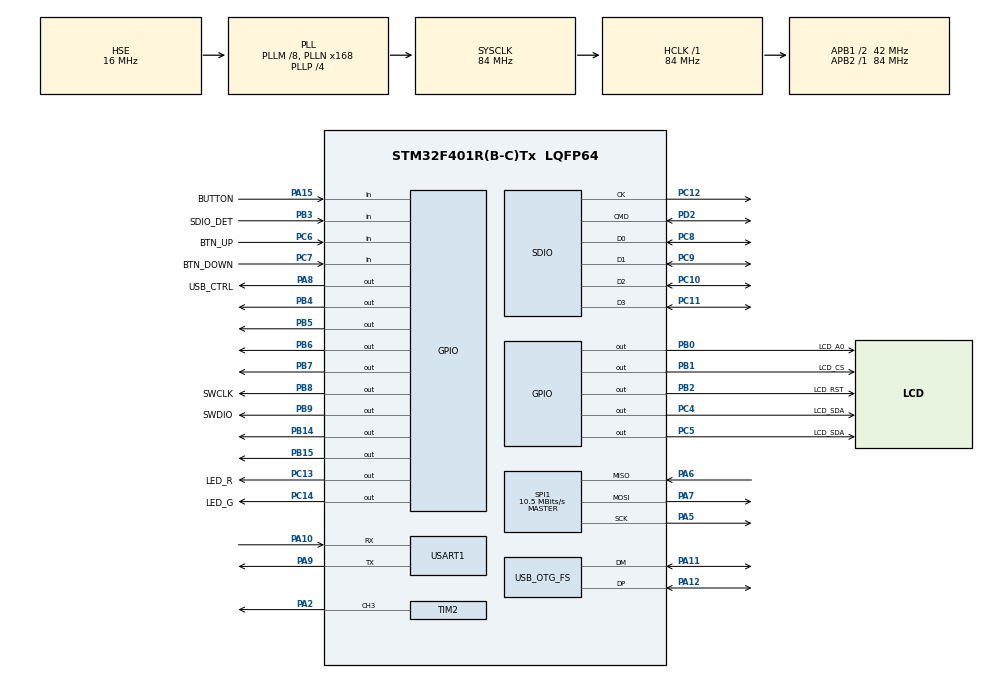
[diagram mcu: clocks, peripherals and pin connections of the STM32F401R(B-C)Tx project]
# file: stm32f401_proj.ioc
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FATFS.BSP.number=1
FATFS._USE_LFN=2
FATFS0.BSP.STBoard=false
FATFS0.BSP.api=Unknown
FATFS0.BSP.instance=PB3
FATFS0.BSP.ip=GPIO
FATFS0.BSP.mode=Input
FATFS0.BSP.name=Detect_SDIO
FATFS0.BSP.solution=PB3
Mcu.Family=STM32F4
Mcu.Name=STM32F401R(B-C)Tx
Mcu.Package=LQFP64
NVIC.OTG_FS_IRQn=true\:0\:0\:false\:false\:true\:false\:true\:true
NVIC.PriorityGroup=NVIC_PRIORITYGROUP_4
PA10.Mode=Asynchronous
PA10.Signal=USART1_RX
PA11.Mode=Device_Only
PA11.Signal=USB_OTG_FS_DM
PA12.Mode=Device_Only
PA12.Signal=USB_OTG_FS_DP
PA13.Mode=Serial_Wire
PA13.Signal=SYS_JTMS-SWDIO
PA14.Mode=Serial_Wire
PA14.Signal=SYS_JTCK-SWCLK
PA15.GPIO_Label=BUTTON
PA15.Signal=GPIO_Input
PA2.Signal=S_TIM2_CH3
PA5.Mode=Full_Duplex_Master
PA5.Signal=SPI1_SCK
PA6.Mode=Full_Duplex_Master
PA6.Signal=SPI1_MISO
PA7.Mode=Full_Duplex_Master
PA7.Signal=SPI1_MOSI
PA8.GPIO_Label=USB_CTRL
PA8.Signal=GPIO_Output
PA9.Mode=Asynchronous
PA9.Signal=USART1_TX
PB0.GPIO_Label=LCD_A0
PB0.Signal=GPIO_Output
PB1.GPIO_Label=LCD_CS
PB1.Signal=GPIO_Output
PB14.Signal=GPIO_Output
PB15.Signal=GPIO_Output
PB2.GPIO_Label=LCD_RST
PB2.Signal=GPIO_Output
PB3.GPIO_Label=SDIO_DET
PB3.Signal=GPIO_Input
PB4.Signal=GPIO_Output
PB5.Signal=GPIO_Output
PB6.Signal=GPIO_Output
PB7.Signal=GPIO_Output
PB8.GPIO_Label=SWCLK
PB8.Signal=GPIO_Output
PB9.GPIO_Label=SWDIO
PB9.Signal=GPIO_Output
PC10.Mode=SD_4_bits_Wide_bus
PC10.Signal=SDIO_D2
PC11.Mode=SD_4_bits_Wide_bus
PC11.Signal=SDIO_D3
PC12.Mode=SD_4_bits_Wide_bus
PC12.Signal=SDIO_CK
PC13-ANTI_TAMP.GPIO_Label=LED_R
PC13-ANTI_TAMP.Signal=GPIO_Output
PC14-OSC32_IN.GPIO_Label=LED_G
PC14-OSC32_IN.Signal=GPIO_Output
PC4.GPIO_Label=LCD_SDA
PC4.Signal=GPIO_Output
PC5.GPIO_Label=LCD_SDA
PC5.Signal=GPIO_Output
PC6.GPIO_Label=BTN_UP
PC6.GPIO_PuPd=GPIO_PULLUP
PC6.Signal=GPIO_Input
PC7.GPIO_Label=BTN_DOWN
PC7.GPIO_PuPd=GPIO_PULLUP
PC7.Signal=GPIO_Input
PC8.Mode=SD_4_bits_Wide_bus
PC8.Signal=SDIO_D0
PC9.Mode=SD_4_bits_Wide_bus
PC9.Signal=SDIO_D1
PD2.Mode=SD_4_bits_Wide_bus
PD2.Signal=SDIO_CMD
PH0\ -\ OSC_IN.Mode=HSE-External-Oscillator
PH0\ -\ OSC_IN.Signal=RCC_OSC_IN
PH1\ -\ OSC_OUT.Mode=HSE-External-Oscillator
PH1\ -\ OSC_OUT.Signal=RCC_OSC_OUT
ProjectManager.HeapSize=0x200
ProjectManager.StackSize=0x1000
ProjectManager.TargetToolchain=MDK-ARM V5.32
RCC.48MHZClocksFreq_Value=48000000
RCC.AHBFreq_Value=84000000
RCC.APB1CLKDivider=RCC_HCLK_DIV2
RCC.APB1Freq_Value=42000000
RCC.APB1TimFreq_Value=84000000
RCC.APB2Freq_Value=84000000
RCC.APB2TimFreq_Value=84000000
RCC.CortexFreq_Value=84000000
RCC.HCLKFreq_Value=84000000
RCC.HSE_VALUE=16000000
RCC.HSI_VALUE=16000000
RCC.LSE_VALUE=32768
RCC.PLLM=8
RCC.PLLN=168
RCC.PLLP=RCC_PLLP_DIV4
RCC.PLLQ=7
RCC.SYSCLKFreq_VALUE=84000000
RCC.SYSCLKSource=RCC_SYSCLKSOURCE_PLLCLK
RCC.VCOOutputFreq_Value=336000000
SDIO.ClockDiv=5
SH.S_TIM2_CH3.0=TIM2_CH3,PWM Generation3 CH3
SPI1.CalculateBaudRate=10.5 MBits/s
SPI1.Direction=SPI_DIRECTION_2LINES
SPI1.Mode=SPI_MODE_MASTER
SPI1.VirtualType=VM_MASTER
TIM2.AutoReloadPreload=TIM_AUTORELOAD_PRELOAD_ENABLE
TIM2.Channel-PWM\ Generation3\ CH3=TIM_CHANNEL_3
TIM2.Period=369
TIM2.Prescaler=83
TIM2.Pulse-PWM\ Generation3\ CH3=185
USART1.VirtualMode=VM_ASYNC
USB_DEVICE.CLASS_NAME_FS=CDC
USB_DEVICE.VirtualMode=Cdc
USB_DEVICE.VirtualModeFS=Cdc_FS
USB_OTG_FS.VirtualMode=Device_Only
VP_FATFS_VS_SDIO.Mode=SDIO
VP_USB_DEVICE_VS_USB_DEVICE_CDC_FS.Mode=CDC_FS
board=custom

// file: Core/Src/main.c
/* USER CODE BEGIN Header */
/**
  ******************************************************************************
  * @file           : main.c
  * @brief          : Main program body
  ******************************************************************************
  * @attention
  *
  * Copyright (c) 2026 STMicroelectronics.
  * All rights reserved.
  *
  * This software is licensed under terms that can be found in the LICENSE file
  * in the root directory of this software component.
  * If no LICENSE file comes with this software, it is provided AS-IS.
  *
  ******************************************************************************
  */
/* USER CODE END Header */
#include "main.h"
#include "fatfs.h"
#include "usb_device.h"

/* USER CODE BEGIN Includes */
#include "app_main.h"
/* USER CODE END Includes */

SD_HandleTypeDef hsd;

SPI_HandleTypeDef hspi1;

TIM_HandleTypeDef htim2;

UART_HandleTypeDef huart1;

void SystemClock_Config(void);
static void MX_GPIO_Init(void);
static void MX_SDIO_SD_Init(void);
static void MX_SPI1_Init(void);
static void MX_USART1_UART_Init(void);
static void MX_TIM2_Init(void);

int main(void)
{

  /* MCU Configuration--------------------------------------------------------*/

  /* Reset of all peripherals, Initializes the Flash interface and the Systick. */
  HAL_Init();

  /* Configure the system clock */
  SystemClock_Config();

  /* Initialize all configured peripherals */
  MX_GPIO_Init();
  MX_SDIO_SD_Init();
  MX_SPI1_Init();
  MX_USART1_UART_Init();
  MX_TIM2_Init();
  MX_FATFS_Init();
  MX_USB_DEVICE_Init();
  /* USER CODE BEGIN 2 */
	  HAL_GPIO_WritePin(USB_CTRL_GPIO_Port, USB_CTRL_Pin, GPIO_PIN_SET);

  /* 复位源打印（IWDG/欠压/软复位一眼分辨，产线诊断用）*/
  {
    uint32_t csr = RCC->CSR;
    const char *src = (csr & (1U << 24)) ? "IWDG" :
                      (csr & (1U << 19)) ? "WWDG" :
                      (csr & (1U << 26)) ? "SOFT" :
                      (csr & (1U << 28)) ? "POR" : "?";
    {   /* 必须 bsp_uart_log：裸 printf 无调试器时走半主机会挂死（实测教训）*/
        extern int bsp_uart_log(const char *fmt, ...);
        bsp_uart_log("[RST] src=%s csr=%08lX\n", src, (unsigned long)csr);
    }
  }
  app_main_init();   /* 应用层初始化：装配 LED 设备等 */
  /* USER CODE END 2 */

  /* Infinite loop */
  while (1)
  {

    /* USER CODE BEGIN 3 */
    app_main_loop();   /* 应用层主循环：LED 闪烁等 */
  }
  /* USER CODE END 3 */
}

void SystemClock_Config(void)
{
  RCC_OscInitTypeDef RCC_OscInitStruct = {0};
  RCC_ClkInitTypeDef RCC_ClkInitStruct = {0};

  /** Configure the main internal regulator output voltage
  */
  __HAL_RCC_PWR_CLK_ENABLE();
  __HAL_PWR_VOLTAGESCALING_CONFIG(PWR_REGULATOR_VOLTAGE_SCALE2);

  /** Initializes the RCC Oscillators according to the specified parameters
  * in the RCC_OscInitTypeDef structure.
  */
  RCC_OscInitStruct.OscillatorType = RCC_OSCILLATORTYPE_HSE;
  RCC_OscInitStruct.HSEState = RCC_HSE_ON;
  RCC_OscInitStruct.PLL.PLLState = RCC_PLL_ON;
  RCC_OscInitStruct.PLL.PLLSource = RCC_PLLSOURCE_HSE;
  RCC_OscInitStruct.PLL.PLLM = 8;
  RCC_OscInitStruct.PLL.PLLN = 168;
  RCC_OscInitStruct.PLL.PLLP = RCC_PLLP_DIV4;
  RCC_OscInitStruct.PLL.PLLQ = 7;
  if (HAL_RCC_OscConfig(&RCC_OscInitStruct) != HAL_OK)
  {
    Error_Handler();
  }

  /** Initializes the CPU, AHB and APB buses clocks
  */
  RCC_ClkInitStruct.ClockType = RCC_CLOCKTYPE_HCLK|RCC_CLOCKTYPE_SYSCLK
                              |RCC_CLOCKTYPE_PCLK1|RCC_CLOCKTYPE_PCLK2;
  RCC_ClkInitStruct.SYSCLKSource = RCC_SYSCLKSOURCE_PLLCLK;
  RCC_ClkInitStruct.AHBCLKDivider = RCC_SYSCLK_DIV1;
  RCC_ClkInitStruct.APB1CLKDivider = RCC_HCLK_DIV2;
  RCC_ClkInitStruct.APB2CLKDivider = RCC_HCLK_DIV1;

  if (HAL_RCC_ClockConfig(&RCC_ClkInitStruct, FLASH_LATENCY_2) != HAL_OK)
  {
    Error_Handler();
  }
}

static void MX_SDIO_SD_Init(void)
{

  hsd.Instance = SDIO;
  hsd.Init.ClockEdge = SDIO_CLOCK_EDGE_RISING;
  hsd.Init.ClockBypass = SDIO_CLOCK_BYPASS_DISABLE;
  hsd.Init.ClockPowerSave = SDIO_CLOCK_POWER_SAVE_DISABLE;
  hsd.Init.BusWide = SDIO_BUS_WIDE_1B;
  /* SDIO 写可靠性（实测 USB CDC + SD 写同跑时 f_write 间歇 FR_DISK_ERR）：
   *  - 硬件流控 ENABLE 实测反而让写立即失败（F401 SDIO 流控硅片 bug）→ 保持 DISABLED
   *  - 根因：轮询喂写 FIFO，USB 中断偶发抢 CPU → FIFO 欠载。降时钟给 CPU 充裕余量。
   *  → ClockDiv 5→30（SDIO_CK≈48/(30+2)=1.5MHz）。读随之变慢但稳定。
   *    后续若要提速，改 SDIO DMA（DMA 喂 FIFO 不抢 CPU）。*/
  hsd.Init.HardwareFlowControl = SDIO_HARDWARE_FLOW_CONTROL_DISABLE;
  hsd.Init.ClockDiv = 30;

}

static void MX_SPI1_Init(void)
{

  /* SPI1 parameter configuration*/
  hspi1.Instance = SPI1;
  hspi1.Init.Mode = SPI_MODE_MASTER;
  hspi1.Init.Direction = SPI_DIRECTION_2LINES;
  hspi1.Init.DataSize = SPI_DATASIZE_8BIT;
  hspi1.Init.CLKPolarity = SPI_POLARITY_LOW;
  hspi1.Init.CLKPhase = SPI_PHASE_1EDGE;
  hspi1.Init.NSS = SPI_NSS_SOFT;
  /* ST7789 SPI 写时序 max 16MHz。APB2=84MHz：/2=42MHz 严重超速 → 局部花屏
   * （实测：红色区花屏、白/绿/蓝正常 —— 0xF800 字节流直流分量最不平衡最易错）。
   * /8=10.5MHz，规格内留 35% 裕量；全屏刷 115KB ≈ 90ms。 */
  hspi1.Init.BaudRatePrescaler = SPI_BAUDRATEPRESCALER_8;
  hspi1.Init.FirstBit = SPI_FIRSTBIT_MSB;
  hspi1.Init.TIMode = SPI_TIMODE_DISABLE;
  hspi1.Init.CRCCalculation = SPI_CRCCALCULATION_DISABLE;
  hspi1.Init.CRCPolynomial = 10;
  if (HAL_SPI_Init(&hspi1) != HAL_OK)
  {
    Error_Handler();
  }

}

static void MX_TIM2_Init(void)
{

  TIM_MasterConfigTypeDef sMasterConfig = {0};
  TIM_OC_InitTypeDef sConfigOC = {0};

  htim2.Instance = TIM2;
  htim2.Init.Prescaler = 83;
  htim2.Init.CounterMode = TIM_COUNTERMODE_UP;
  htim2.Init.Period = 369;
  htim2.Init.ClockDivision = TIM_CLOCKDIVISION_DIV1;
  htim2.Init.AutoReloadPreload = TIM_AUTORELOAD_PRELOAD_ENABLE;
  if (HAL_TIM_PWM_Init(&htim2) != HAL_OK)
  {
    Error_Handler();
  }
  sMasterConfig.MasterOutputTrigger = TIM_TRGO_RESET;
  sMasterConfig.MasterSlaveMode = TIM_MASTERSLAVEMODE_DISABLE;
  if (HAL_TIMEx_MasterConfigSynchronization(&htim2, &sMasterConfig) != HAL_OK)
  {
    Error_Handler();
  }
  sConfigOC.OCMode = TIM_OCMODE_PWM1;
  sConfigOC.Pulse = 185;
  sConfigOC.OCPolarity = TIM_OCPOLARITY_HIGH;
  sConfigOC.OCFastMode = TIM_OCFAST_DISABLE;
  if (HAL_TIM_PWM_ConfigChannel(&htim2, &sConfigOC, TIM_CHANNEL_3) != HAL_OK)
  {
    Error_Handler();
  }
  HAL_TIM_MspPostInit(&htim2);

}

static void MX_USART1_UART_Init(void)
{

  huart1.Instance = USART1;
  huart1.Init.BaudRate = 115200;
  huart1.Init.WordLength = UART_WORDLENGTH_8B;
  huart1.Init.StopBits = UART_STOPBITS_1;
  huart1.Init.Parity = UART_PARITY_NONE;
  huart1.Init.Mode = UART_MODE_TX_RX;
  huart1.Init.HwFlowCtl = UART_HWCONTROL_NONE;
  huart1.Init.OverSampling = UART_OVERSAMPLING_16;
  if (HAL_UART_Init(&huart1) != HAL_OK)
  {
    Error_Handler();
  }

}

static void MX_GPIO_Init(void)
{
  GPIO_InitTypeDef GPIO_InitStruct = {0};

  /* GPIO Ports Clock Enable */
  __HAL_RCC_GPIOC_CLK_ENABLE();
  __HAL_RCC_GPIOH_CLK_ENABLE();
  __HAL_RCC_GPIOA_CLK_ENABLE();
  __HAL_RCC_GPIOB_CLK_ENABLE();
  __HAL_RCC_GPIOD_CLK_ENABLE();

  /*Configure GPIO pin Output Level */
  HAL_GPIO_WritePin(GPIOC, LED_R_Pin|LED_G_Pin|LCD_SDA_Pin|LCD_SDAC5_Pin
                          |GPIO_PIN_6|GPIO_PIN_7, GPIO_PIN_RESET);

  /*Configure GPIO pin Output Level */
  HAL_GPIO_WritePin(GPIOB, LCD_A0_Pin|LCD_CS_Pin|LCD_RST_Pin|GPIO_PIN_14
                          |GPIO_PIN_15|GPIO_PIN_4|GPIO_PIN_5|GPIO_PIN_6
                          |GPIO_PIN_7|SWCLK_Pin|SWDIO_Pin, GPIO_PIN_RESET);

  /*Configure GPIO pin Output Level */
  HAL_GPIO_WritePin(USB_CTRL_GPIO_Port, USB_CTRL_Pin, GPIO_PIN_RESET);

  /*Configure GPIO pins : LED_R_Pin LED_G_Pin LCD_SDA_Pin LCD_SDAC5_Pin
                           PC6 PC7 */
  GPIO_InitStruct.Pin = LED_R_Pin|LED_G_Pin|LCD_SDA_Pin|LCD_SDAC5_Pin
                          |GPIO_PIN_6|GPIO_PIN_7;
  GPIO_InitStruct.Mode = GPIO_MODE_OUTPUT_PP;
  GPIO_InitStruct.Pull = GPIO_NOPULL;
  GPIO_InitStruct.Speed = GPIO_SPEED_FREQ_LOW;
  HAL_GPIO_Init(GPIOC, &GPIO_InitStruct);

  /*Configure GPIO pins : LCD_A0_Pin LCD_CS_Pin LCD_RST_Pin PB14
                           PB15 PB4 PB5 PB6
                           PB7 SWCLK_Pin SWDIO_Pin */
  GPIO_InitStruct.Pin = LCD_A0_Pin|LCD_CS_Pin|LCD_RST_Pin|GPIO_PIN_14
                          |GPIO_PIN_15|GPIO_PIN_4|GPIO_PIN_5|GPIO_PIN_6
                          |GPIO_PIN_7|SWCLK_Pin|SWDIO_Pin;
  GPIO_InitStruct.Mode = GPIO_MODE_OUTPUT_PP;
  GPIO_InitStruct.Pull = GPIO_NOPULL;
  GPIO_InitStruct.Speed = GPIO_SPEED_FREQ_LOW;
  HAL_GPIO_Init(GPIOB, &GPIO_InitStruct);

  /*Configure GPIO pin : USB_CTRL_Pin */
  GPIO_InitStruct.Pin = USB_CTRL_Pin;
  GPIO_InitStruct.Mode = GPIO_MODE_OUTPUT_PP;
  GPIO_InitStruct.Pull = GPIO_NOPULL;
  GPIO_InitStruct.Speed = GPIO_SPEED_FREQ_LOW;
  HAL_GPIO_Init(USB_CTRL_GPIO_Port, &GPIO_InitStruct);

  /*Configure GPIO pin : BUTTON_Pin */
  GPIO_InitStruct.Pin = BUTTON_Pin;
  GPIO_InitStruct.Mode = GPIO_MODE_INPUT;
  GPIO_InitStruct.Pull = GPIO_NOPULL;
  HAL_GPIO_Init(BUTTON_GPIO_Port, &GPIO_InitStruct);

  /*Configure GPIO pin : SDIO_DET_Pin */
  GPIO_InitStruct.Pin = SDIO_DET_Pin;
  GPIO_InitStruct.Mode = GPIO_MODE_INPUT;
  GPIO_InitStruct.Pull = GPIO_NOPULL;
  HAL_GPIO_Init(SDIO_DET_GPIO_Port, &GPIO_InitStruct);

}

void Error_Handler(void)
{
  __disable_irq();
  while (1)
  {
  }
}
